# MDR1986VE81 register map
Vendor: Milandr; Series: ARMCM4; File version: 2.0
CPU: CM4 r0p0, little endian, MPU, FPU, 3 interrupt priority bits
Registers are 32-bit, read-write, reset 0x0 unless marked. A register's access mark holds for its fields unless they carry their own. Offsets are from the block's base; [hi:lo] are bit positions; {n}, {i} and the like mark numbered series; 'fields as' and 'values as' point back to an identical list.

## MDR_ETH1 — Ethernet Control
Base 0x21000000
0x00 DELIMETER 16-bit reset 0x1000 — Slit EthMem to FIFO_Rx and FIFO_Tx
0x02 MAC_L 16-bit reset 0x12 — MAC low bits
0x04 MAC_M 16-bit reset 0x3456 — MAC middle bits
0x06 MAC_H 16-bit reset 0x78AB — MAC high bits
{0x8+2i} HASH{i} 16-bit (i=0..3) — HASH of MAC to filter multycast
0x10 IPG 16-bit reset 0x60 — Inter Packet Gap
0x12 PSC 16-bit reset 0x31 — Prescaller of ETH_Clock to get TimeStep
0x14 BAG 16-bit reset 0x63 — Frame Send Period in DetermMode
0x16 JitterWnd 16-bit reset 0x4 — BAG's Jitter to start transfer
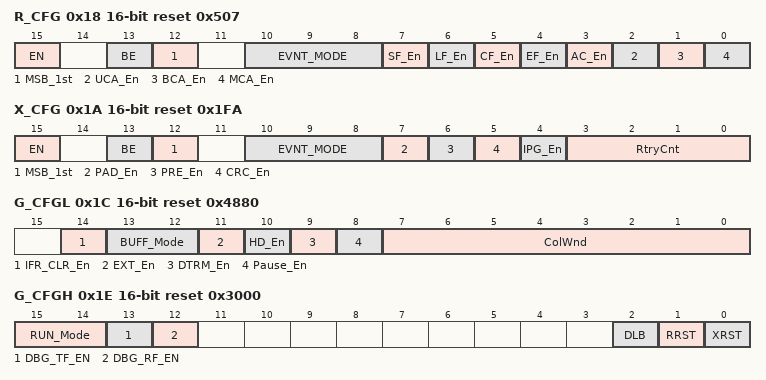
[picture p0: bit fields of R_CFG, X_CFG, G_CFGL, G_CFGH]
0x18 R_CFG 16-bit reset 0x507 — RX Config Register
  [15] EN — Enable Receiver
    0=Off (Disable); 1=On (Enable)
  [13] BE — Byte order
    0=LittleEndian; 1=BigEndian
  [12] MSB_1st — Bit order
    0=LSB (Low bit forward); 1=MSB (High bit forward)
  [10:8] EVNT_MODE — Select signal EVNT1 events
    0=FIFO_Empty (FIFO is empty); 1=FIFO_AEmpty (FIFO is 1/32 full); 2=FIFO_Half (FIFO is 1/2 full); 3=FIFO_AFull (FIFO is 31/32 full); 4=FIFO_Full; 5=Received (Frame received); 6=Saved (Frame saved to buff); 7=Fault (Frame in wrong)
  [7] SF_En — Accept Short frames
    0=Off (Disable); 1=On (Enable)
  [6] LF_En — Accept Long frames
    0=Off (Disable); 1=On (Enable)
  [5] CF_En — Accept Control frames
    0=Off (Disable); 1=On (Enable)
  [4] EF_En — Accept frames with errors
    0=Off (Disable); 1=On (Enable)
  [3] AC_En — Accept Any MAC
    0=Off (Disable); 1=On (Enable)
  [2] UCA_En — Accept Unicast frames
    0=Off (Disable); 1=On (Enable)
  [1] BCA_En — Accept Broadcast frames
    0=Off (Disable); 1=On (Enable)
  [0] MCA_En — Accept Multycast frames
    0=Off (Disable); 1=On (Enable)
0x1A X_CFG 16-bit reset 0x1FA — TX Config Register
  [15] EN — Enable Transmitter
    0=Off (Disable); 1=On (Enable)
  [13] BE — Byte order
    0=LittleEndian; 1=BigEndian
  [12] MSB_1st — Bit order
    0=LSB (Low bit forward); 1=MSB (High bit forward)
  [10:8] EVNT_MODE — Select signal EVNT1 events
    0=FIFO_Empty (FIFO is empty); 1=FIFO_AEmpty (FIFO is 1/32 full); 2=FIFO_Half (FIFO is 1/2 full); 3=FIFO_AFull (FIFO is 31/32 full); 4=FIFO_Full; 5=Sent (Frame sent); 6=Read (Frame read from buff); 7=TryStarted (Start sending)
  [7] PAD_En — Fill with PAD to minimum length
    0=Off (Disable); 1=On (Enable)
  [6] PRE_En — Add Preamble to frame
    0=Off (Disable); 1=On (Enable)
  [5] CRC_En — Add CRC to frame
    0=Off (Disable); 1=On (Enable)
  [4] IPG_En — IPG enable
    0=Off (Disable); 1=On (Enable)
  [3:0] RtryCnt — Try send count
0x1C G_CFGL 16-bit reset 0x4880 — Global Config Register1
  [14] IFR_CLR_En — Clear IFR status on Read
    0=Off (Disable); 1=On (Enable)
  [13:12] BUFF_Mode — Buffer control
    0=Linear (User PTR Control); 1=Auto PTR Control; 2=FIFO (FIFO Buff Control)
  [11] EXT_En — Fill frame to slot time
    0=Off (Disable); 1=On (Enable)
  [10] HD_En — Enable Half duples
    0=Off (Disable); 1=On (Enable)
  [9] DTRM_En — DetermMode
    0=Off (Disable); 1=On (Enable)
  [8] Pause_En — Accept Pause frame
    0=Off (Disable); 1=On (Enable)
  [7:0] ColWnd — Collision window in bits mul 4
0x1E G_CFGH 16-bit reset 0x3000 — Global Config Register2
  [15:14] RUN_Mode — Work mode
    0=FreeRun (Work mode); 1=Halt (Debug Halt mode); 2=Stop (Debug Stop mode)
  [13] DBG_TF_EN — Enable Auto PTR_TX
    0=Off (Disable); 1=On (Enable)
  [12] DBG_RF_EN — Enable Auto PTR_RX
    0=Off (Disable); 1=On (Enable)
  [2] DLB — Dig Loopback
    0=Off (Disable); 1=On (Enable)
  [1] RRST — Reset Receiver
    0=Off (Disable); 1=On (Enable)
  [0] XRST — Reset Transmitter
    0=Off (Disable); 1=On (Enable)
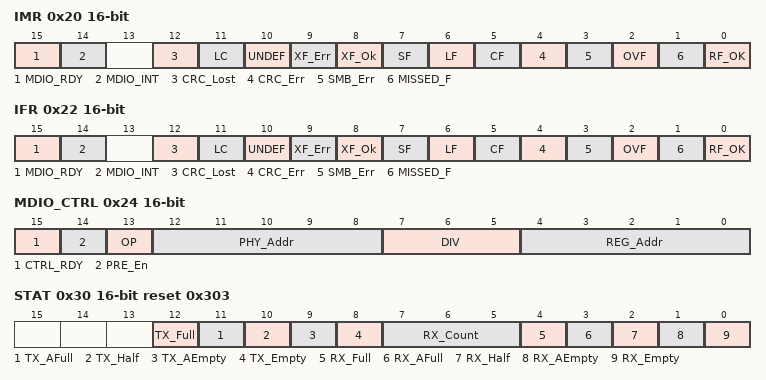
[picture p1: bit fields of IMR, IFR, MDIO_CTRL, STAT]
0x20 IMR 16-bit (reset mask 0xBFFF) — IRQ Mask Register
  [all] fields
    0=Off (Disable); 1=On (Enable)
  [15] MDIO_RDY — MDIO transfer completed
  [14] MDIO_INT — IRQ from MDIO
  [12] CRC_Lost — Carrier sense lost
  [11] LC — Late Collision
  [10] UNDEF — Tx buff empty
  [9] XF_Err — Error on sending
  [8] XF_Ok — Sent successful
  [7] SF — Short frame received
  [6] LF — Long frame received
  [5] CF — Control frame received
  [4] CRC_Err — CRC error
  [3] SMB_Err — Receiving error
  [2] OVF — Buff RX overflow
  [1] MISSED_F — Not enough space in buff RX
  [0] RF_OK — Received OK
0x22 IFR 16-bit (reset mask 0xBFFF) — IRQ flag register
  fields as IMR
0x24 MDIO_CTRL 16-bit — MDIO Control Register
  [15] CTRL_RDY — Command and Status flag
    0=Busy (No preamble); 1=Start_Compl (WR_Start and RD_completed)
  [14] PRE_En — Send preamble of 0xFFFF_FFFF
    0=Off (No preamble); 1=On (Send preamble)
  [13] OP — Operation RD or WR
    0=WR (MDIO Write); 1=RD (MDIO Read)
  [12:8] PHY_Addr — PHY address at MDIO Bus
  [7:5] DIV — ETH_CLK to MDIO bitrate
  [4:0] REG_Addr — PHY_Reg address address at MDIO Bus
0x26 MDIO_DATA 16-bit
0x28 R_HEAD 16-bit — PTR to start of received data
0x2A X_TAIL 16-bit — PTR to write data
0x2C R_TAIL 16-bit ro — PTR to end of received data
0x2E X_HEAD 16-bit ro — PTR to start of data to send
0x30 STAT 16-bit reset 0x303 — Status Register
  [12] TX_Full — TX_FIFO is full
    0=Off (No event); 1=On (Event)
  [11] TX_AFull — TX_FIFO is 31/32 full
    0=Off (No event); 1=On (Event)
  [10] TX_Half — TX_FIFO is 1/2 full
    0=Off (No event); 1=On (Event)
  [9] TX_AEmpty — TX_FIFO is 1/32 full
    0=Off (No event); 1=On (Event)
  [8] TX_Empty — TX_FIFO is Empty
    0=Off (No event); 1=On (Event)
  [7:5] RX_Count — Frames in FIFO
    {v}=FramesRD_{v} (Frames to read) (v=0..7)
  [4] RX_Full — RX_FIFO is full
    0=Off (No event); 1=On (Event)
  [3] RX_AFull — RX_FIFO is 31/32 full
    0=Off (No event); 1=On (Event)
  [2] RX_Half — RX_FIFO is 1/2 full
    0=Off (No event); 1=On (Event)
  [1] RX_AEmpty — RX_FIFO is 1/32 full
    0=Off (No event); 1=On (Event)
  [0] RX_Empty — RX_FIFO empty
    0=Off (No event); 1=On (Event)
0x32 RCOUNTER 16-bit ro — Frame Received in Total
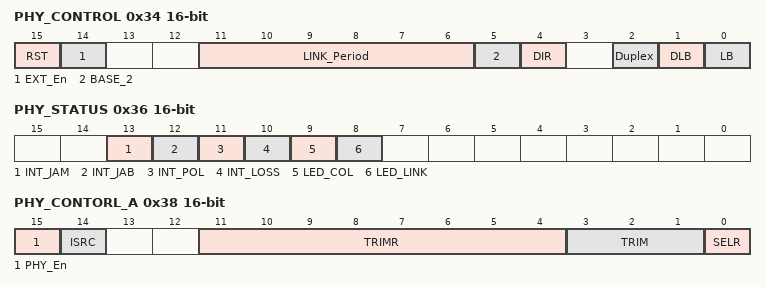
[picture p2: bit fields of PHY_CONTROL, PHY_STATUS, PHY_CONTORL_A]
0x34 PHY_CONTROL 16-bit
  [15] RST — PHY Reset
    0=Reset State; 1=Work State
  [14] EXT_En — External PHY enable
    0=Off (Disabled); 1=On (Enabled)
  [11:6] LINK_Period
  [5] BASE_2 — Cable seelct
    0=Twin Pair cable; 1=Coaxial cable
  [4] DIR — Bit Order
    0=Standard bits direction; 1=Inverted bits direction
  [2] Duplex — Digital LoopBack
    0=Full Duplex; 1=Half Duplex
  [1] DLB — Digital LoopBack
    0=Off (Disabled); 1=On (Enabled)
  [0] LB — Analog LoopBack
    0=Off (Disabled); 1=On (Enabled)
0x36 PHY_STATUS 16-bit
  [all] fields
    0=Off (No Event); 1=On (Event)
  [13] INT_JAM — JAM signal received
  [12] INT_JAB — Long frame received
  [11] INT_POL — Link Pulse inverted
  [10] INT_LOSS — Link Lost
  [9] LED_COL — Collision Indicator
  [8] LED_LINK — Link Indicator
0x38 PHY_CONTORL_A 16-bit — PHY Control Extra Register
  [15] PHY_En — PHY Enable
    0=Disable (PHY Disabled); 1=Enable (PHY Enabled)
  [14] ISRC — I source select
    0=U_le4V (for Ucc less than 4V); 1=U_gt4V (for Ucc greater than 4V)
  [11:4] TRIMR — Select I_Ref
  [3:1] TRIM — Trin internal U_Ref
    0=Uref_1v25 (Internal Uref Trim); 1=Uref_1v23 (Internal Uref Trim); 2=Uref_1v22 (Internal Uref Trim); 3=Uref_1v20 (Internal Uref Trim); 4=Uref_1v19 (Internal Uref Trim); 5=Uref_1v17 (Internal Uref Trim); 6=Uref_1v16 (Internal Uref Trim); 7=Uref_1v15 (Internal Uref Trim)
  [0] SELR — Select U_Ref source
    0=Internal (EXTR pin in Z-state); 1=External (Use external R on EXTR pin)
